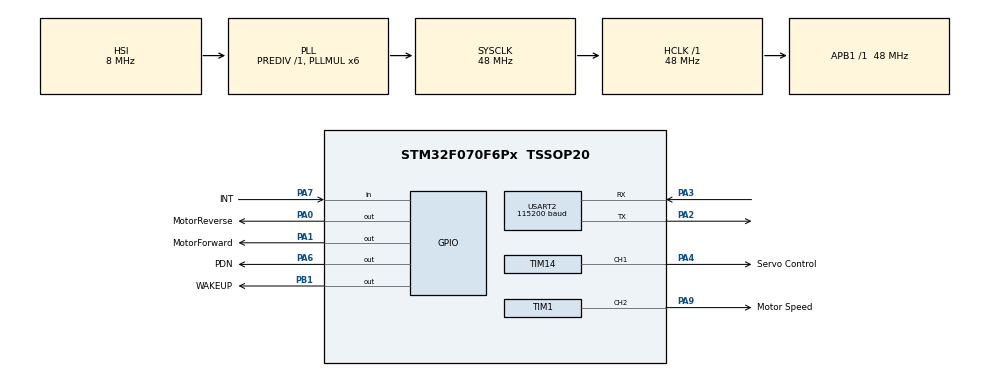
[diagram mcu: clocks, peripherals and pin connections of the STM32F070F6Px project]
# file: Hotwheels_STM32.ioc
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Mcu.Family=STM32F0
Mcu.Name=STM32F070F6Px
Mcu.Package=TSSOP20
NVIC.USART2_IRQn=true\:0\:0\:false\:false\:true\:true\:true\:true
PA0.GPIO_Label=MotorReverse
PA0.Signal=GPIO_Output
PA1.GPIO_Label=MotorForward
PA1.Signal=GPIO_Output
PA13.Mode=Serial_Wire
PA13.Signal=SYS_SWDIO
PA14.Mode=Serial_Wire
PA14.Signal=SYS_SWCLK
PA2.Mode=Asynchronous
PA2.Signal=USART2_TX
PA3.Mode=Asynchronous
PA3.Signal=USART2_RX
PA4.GPIO_Label=Servo Control
PA4.Signal=S_TIM14_CH1
PA6.GPIO_Label=PDN
PA6.Signal=GPIO_Output
PA7.GPIO_Label=INT
PA7.Signal=GPIO_Input
PA9.GPIO_Label=Motor Speed
PA9.Signal=S_TIM1_CH2
PB1.GPIO_Label=WAKEUP
PB1.Signal=GPIO_Output
PF0-OSC_IN.Mode=HSE-External-Oscillator
PF0-OSC_IN.Signal=RCC_OSC_IN
PF1-OSC_OUT.Mode=HSE-External-Oscillator
PF1-OSC_OUT.Signal=RCC_OSC_OUT
ProjectManager.HeapSize=0x200
ProjectManager.StackSize=0x400
ProjectManager.TargetToolchain=STM32CubeIDE
RCC.AHBFreq_Value=48000000
RCC.APB1Freq_Value=48000000
RCC.APB1TimFreq_Value=48000000
RCC.HCLKFreq_Value=48000000
RCC.PLLMUL=RCC_PLL_MUL6
RCC.SYSCLKFreq_VALUE=48000000
RCC.SYSCLKSource=RCC_SYSCLKSOURCE_PLLCLK
SH.S_TIM14_CH1.0=TIM14_CH1,PWM Generation1 CH1
SH.S_TIM1_CH2.0=TIM1_CH2,PWM Generation2 CH2
TIM1.Channel-PWM\ Generation2\ CH2=TIM_CHANNEL_2
TIM14.Channel=TIM_CHANNEL_1
USART2.BaudRate=115200
USART2.VirtualMode-Asynchronous=VM_ASYNC
VP_TIM14_VS_ClockSourceINT.Mode=Enable_Timer
VP_TIM1_VS_ClockSourceINT.Mode=Internal
board=custom

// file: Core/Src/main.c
/* USER CODE BEGIN Header */
/**
  ******************************************************************************
  * @file           : main.c
  * @brief          : Main program body
  ******************************************************************************
  * @attention
  *
  * Copyright (c) 2023 STMicroelectronics.
  * All rights reserved.
  *
  * This software is licensed under terms that can be found in the LICENSE file
  * in the root directory of this software component.
  * If no LICENSE file comes with this software, it is provided AS-IS.
  *
  ******************************************************************************
  */
/* USER CODE END Header */
#include "main.h"

/* USER CODE BEGIN Includes */
#include "nRF24_Defs.h"
#include "nRF24.h"
/* USER CODE END Includes */

TIM_HandleTypeDef htim1;
TIM_HandleTypeDef htim14;

UART_HandleTypeDef huart2;

void SystemClock_Config(void);
static void MX_GPIO_Init(void);
static void MX_TIM1_Init(void);
static void MX_TIM14_Init(void);
static void MX_USART2_UART_Init(void);

int main(void)
{

  /* MCU Configuration--------------------------------------------------------*/

  /* Reset of all peripherals, Initializes the Flash interface and the Systick. */
  HAL_Init();

  /* Configure the system clock */
  SystemClock_Config();

  /* Initialize all configured peripherals */
  MX_GPIO_Init();
  MX_TIM1_Init();
  MX_TIM14_Init();
  MX_USART2_UART_Init();

  /* Infinite loop */
  while (1)
  {

  }
}

void SystemClock_Config(void)
{
  RCC_OscInitTypeDef RCC_OscInitStruct = {0};
  RCC_ClkInitTypeDef RCC_ClkInitStruct = {0};

  /** Initializes the RCC Oscillators according to the specified parameters
  * in the RCC_OscInitTypeDef structure.
  */
  RCC_OscInitStruct.OscillatorType = RCC_OSCILLATORTYPE_HSI;
  RCC_OscInitStruct.HSIState = RCC_HSI_ON;
  RCC_OscInitStruct.HSICalibrationValue = RCC_HSICALIBRATION_DEFAULT;
  RCC_OscInitStruct.PLL.PLLState = RCC_PLL_ON;
  RCC_OscInitStruct.PLL.PLLSource = RCC_PLLSOURCE_HSI;
  RCC_OscInitStruct.PLL.PLLMUL = RCC_PLL_MUL6;
  RCC_OscInitStruct.PLL.PREDIV = RCC_PREDIV_DIV1;
  if (HAL_RCC_OscConfig(&RCC_OscInitStruct) != HAL_OK)
  {
    Error_Handler();
  }

  /** Initializes the CPU, AHB and APB buses clocks
  */
  RCC_ClkInitStruct.ClockType = RCC_CLOCKTYPE_HCLK|RCC_CLOCKTYPE_SYSCLK
                              |RCC_CLOCKTYPE_PCLK1;
  RCC_ClkInitStruct.SYSCLKSource = RCC_SYSCLKSOURCE_PLLCLK;
  RCC_ClkInitStruct.AHBCLKDivider = RCC_SYSCLK_DIV1;
  RCC_ClkInitStruct.APB1CLKDivider = RCC_HCLK_DIV1;

  if (HAL_RCC_ClockConfig(&RCC_ClkInitStruct, FLASH_LATENCY_1) != HAL_OK)
  {
    Error_Handler();
  }
}

static void MX_TIM1_Init(void)
{

  TIM_ClockConfigTypeDef sClockSourceConfig = {0};
  TIM_MasterConfigTypeDef sMasterConfig = {0};
  TIM_OC_InitTypeDef sConfigOC = {0};
  TIM_BreakDeadTimeConfigTypeDef sBreakDeadTimeConfig = {0};

  htim1.Instance = TIM1;
  htim1.Init.Prescaler = 0;
  htim1.Init.CounterMode = TIM_COUNTERMODE_UP;
  htim1.Init.Period = 65535;
  htim1.Init.ClockDivision = TIM_CLOCKDIVISION_DIV1;
  htim1.Init.RepetitionCounter = 0;
  htim1.Init.AutoReloadPreload = TIM_AUTORELOAD_PRELOAD_DISABLE;
  if (HAL_TIM_Base_Init(&htim1) != HAL_OK)
  {
    Error_Handler();
  }
  sClockSourceConfig.ClockSource = TIM_CLOCKSOURCE_INTERNAL;
  if (HAL_TIM_ConfigClockSource(&htim1, &sClockSourceConfig) != HAL_OK)
  {
    Error_Handler();
  }
  if (HAL_TIM_PWM_Init(&htim1) != HAL_OK)
  {
    Error_Handler();
  }
  sMasterConfig.MasterOutputTrigger = TIM_TRGO_RESET;
  sMasterConfig.MasterSlaveMode = TIM_MASTERSLAVEMODE_DISABLE;
  if (HAL_TIMEx_MasterConfigSynchronization(&htim1, &sMasterConfig) != HAL_OK)
  {
    Error_Handler();
  }
  sConfigOC.OCMode = TIM_OCMODE_PWM1;
  sConfigOC.Pulse = 0;
  sConfigOC.OCPolarity = TIM_OCPOLARITY_HIGH;
  sConfigOC.OCNPolarity = TIM_OCNPOLARITY_HIGH;
  sConfigOC.OCFastMode = TIM_OCFAST_DISABLE;
  sConfigOC.OCIdleState = TIM_OCIDLESTATE_RESET;
  sConfigOC.OCNIdleState = TIM_OCNIDLESTATE_RESET;
  if (HAL_TIM_PWM_ConfigChannel(&htim1, &sConfigOC, TIM_CHANNEL_2) != HAL_OK)
  {
    Error_Handler();
  }
  sBreakDeadTimeConfig.OffStateRunMode = TIM_OSSR_DISABLE;
  sBreakDeadTimeConfig.OffStateIDLEMode = TIM_OSSI_DISABLE;
  sBreakDeadTimeConfig.LockLevel = TIM_LOCKLEVEL_OFF;
  sBreakDeadTimeConfig.DeadTime = 0;
  sBreakDeadTimeConfig.BreakState = TIM_BREAK_DISABLE;
  sBreakDeadTimeConfig.BreakPolarity = TIM_BREAKPOLARITY_HIGH;
  sBreakDeadTimeConfig.AutomaticOutput = TIM_AUTOMATICOUTPUT_DISABLE;
  if (HAL_TIMEx_ConfigBreakDeadTime(&htim1, &sBreakDeadTimeConfig) != HAL_OK)
  {
    Error_Handler();
  }
  HAL_TIM_MspPostInit(&htim1);

}

static void MX_TIM14_Init(void)
{

  TIM_OC_InitTypeDef sConfigOC = {0};

  htim14.Instance = TIM14;
  htim14.Init.Prescaler = 0;
  htim14.Init.CounterMode = TIM_COUNTERMODE_UP;
  htim14.Init.Period = 65535;
  htim14.Init.ClockDivision = TIM_CLOCKDIVISION_DIV1;
  htim14.Init.AutoReloadPreload = TIM_AUTORELOAD_PRELOAD_DISABLE;
  if (HAL_TIM_Base_Init(&htim14) != HAL_OK)
  {
    Error_Handler();
  }
  if (HAL_TIM_PWM_Init(&htim14) != HAL_OK)
  {
    Error_Handler();
  }
  sConfigOC.OCMode = TIM_OCMODE_PWM1;
  sConfigOC.Pulse = 0;
  sConfigOC.OCPolarity = TIM_OCPOLARITY_HIGH;
  sConfigOC.OCFastMode = TIM_OCFAST_DISABLE;
  if (HAL_TIM_PWM_ConfigChannel(&htim14, &sConfigOC, TIM_CHANNEL_1) != HAL_OK)
  {
    Error_Handler();
  }
  HAL_TIM_MspPostInit(&htim14);

}

static void MX_USART2_UART_Init(void)
{

  huart2.Instance = USART2;
  huart2.Init.BaudRate = 115200;
  huart2.Init.WordLength = UART_WORDLENGTH_8B;
  huart2.Init.StopBits = UART_STOPBITS_1;
  huart2.Init.Parity = UART_PARITY_NONE;
  huart2.Init.Mode = UART_MODE_TX_RX;
  huart2.Init.HwFlowCtl = UART_HWCONTROL_NONE;
  huart2.Init.OverSampling = UART_OVERSAMPLING_16;
  huart2.Init.OneBitSampling = UART_ONE_BIT_SAMPLE_DISABLE;
  huart2.AdvancedInit.AdvFeatureInit = UART_ADVFEATURE_NO_INIT;
  if (HAL_UART_Init(&huart2) != HAL_OK)
  {
    Error_Handler();
  }

}

static void MX_GPIO_Init(void)
{
  GPIO_InitTypeDef GPIO_InitStruct = {0};

  /* GPIO Ports Clock Enable */
  __HAL_RCC_GPIOF_CLK_ENABLE();
  __HAL_RCC_GPIOA_CLK_ENABLE();
  __HAL_RCC_GPIOB_CLK_ENABLE();

  /*Configure GPIO pin Output Level */
  HAL_GPIO_WritePin(GPIOA, MotorReverse_Pin|MotorForward_Pin|PDN_Pin, GPIO_PIN_RESET);

  /*Configure GPIO pin Output Level */
  HAL_GPIO_WritePin(WAKEUP_GPIO_Port, WAKEUP_Pin, GPIO_PIN_RESET);

  /*Configure GPIO pins : MotorReverse_Pin MotorForward_Pin PDN_Pin */
  GPIO_InitStruct.Pin = MotorReverse_Pin|MotorForward_Pin|PDN_Pin;
  GPIO_InitStruct.Mode = GPIO_MODE_OUTPUT_PP;
  GPIO_InitStruct.Pull = GPIO_NOPULL;
  GPIO_InitStruct.Speed = GPIO_SPEED_FREQ_LOW;
  HAL_GPIO_Init(GPIOA, &GPIO_InitStruct);

  /*Configure GPIO pin : INT_Pin */
  GPIO_InitStruct.Pin = INT_Pin;
  GPIO_InitStruct.Mode = GPIO_MODE_INPUT;
  GPIO_InitStruct.Pull = GPIO_NOPULL;
  HAL_GPIO_Init(INT_GPIO_Port, &GPIO_InitStruct);

  /*Configure GPIO pin : WAKEUP_Pin */
  GPIO_InitStruct.Pin = WAKEUP_Pin;
  GPIO_InitStruct.Mode = GPIO_MODE_OUTPUT_PP;
  GPIO_InitStruct.Pull = GPIO_NOPULL;
  GPIO_InitStruct.Speed = GPIO_SPEED_FREQ_LOW;
  HAL_GPIO_Init(WAKEUP_GPIO_Port, &GPIO_InitStruct);

}

void Error_Handler(void)
{
  __disable_irq();
  while (1)
  {
  }
}
